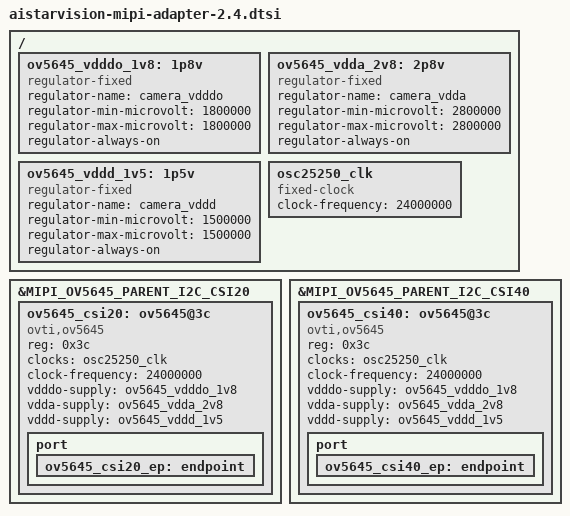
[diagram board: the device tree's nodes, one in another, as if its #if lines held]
// SPDX-License-Identifier: GPL-2.0
/*
 * Device Tree Source for the AISTARVISION MIPI Adapter V2.4
 *
 * Copyright (C) 2021 Renesas Electronics Corp.
 */

/ {
	ov5645_vdddo_1v8: 1p8v {
		compatible = "regulator-fixed";
		regulator-name = "camera_vdddo";
		regulator-min-microvolt = <1800000>;
		regulator-max-microvolt = <1800000>;
		regulator-always-on;
	};

	ov5645_vdda_2v8: 2p8v {
		compatible = "regulator-fixed";
		regulator-name = "camera_vdda";
		regulator-min-microvolt = <2800000>;
		regulator-max-microvolt = <2800000>;
		regulator-always-on;
	};

	ov5645_vddd_1v5: 1p5v {
		compatible = "regulator-fixed";
		regulator-name = "camera_vddd";
		regulator-min-microvolt = <1500000>;
		regulator-max-microvolt = <1500000>;
		regulator-always-on;
	};

	osc25250_clk: osc25250_clk {
		compatible = "fixed-clock";
		#clock-cells = <0>;
		clock-frequency = <24000000>;
	};
};

#ifdef MIPI_OV5645_PARENT_I2C_CSI20
&MIPI_OV5645_PARENT_I2C_CSI20 {
	ov5645_csi20: ov5645@3c {
		compatible = "ovti,ov5645";
		reg = <0x3c>;
		clock-names = "xclk";
		clocks = <&osc25250_clk>;
		clock-frequency = <24000000>;
		vdddo-supply = <&ov5645_vdddo_1v8>;
		vdda-supply = <&ov5645_vdda_2v8>;
		vddd-supply = <&ov5645_vddd_1v5>;

		port {
			ov5645_csi20_ep: endpoint {
			};
		};
	};
};
#endif

#ifdef MIPI_OV5645_PARENT_I2C_CSI40
&MIPI_OV5645_PARENT_I2C_CSI40 {
	ov5645_csi40: ov5645@3c {
		compatible = "ovti,ov5645";
		reg = <0x3c>;
		clock-names = "xclk";
		clocks = <&osc25250_clk>;
		clock-frequency = <24000000>;
		vdddo-supply = <&ov5645_vdddo_1v8>;
		vdda-supply = <&ov5645_vdda_2v8>;
		vddd-supply = <&ov5645_vddd_1v5>;

		port {
			ov5645_csi40_ep: endpoint {
			};
		};
	};
};
#endif
